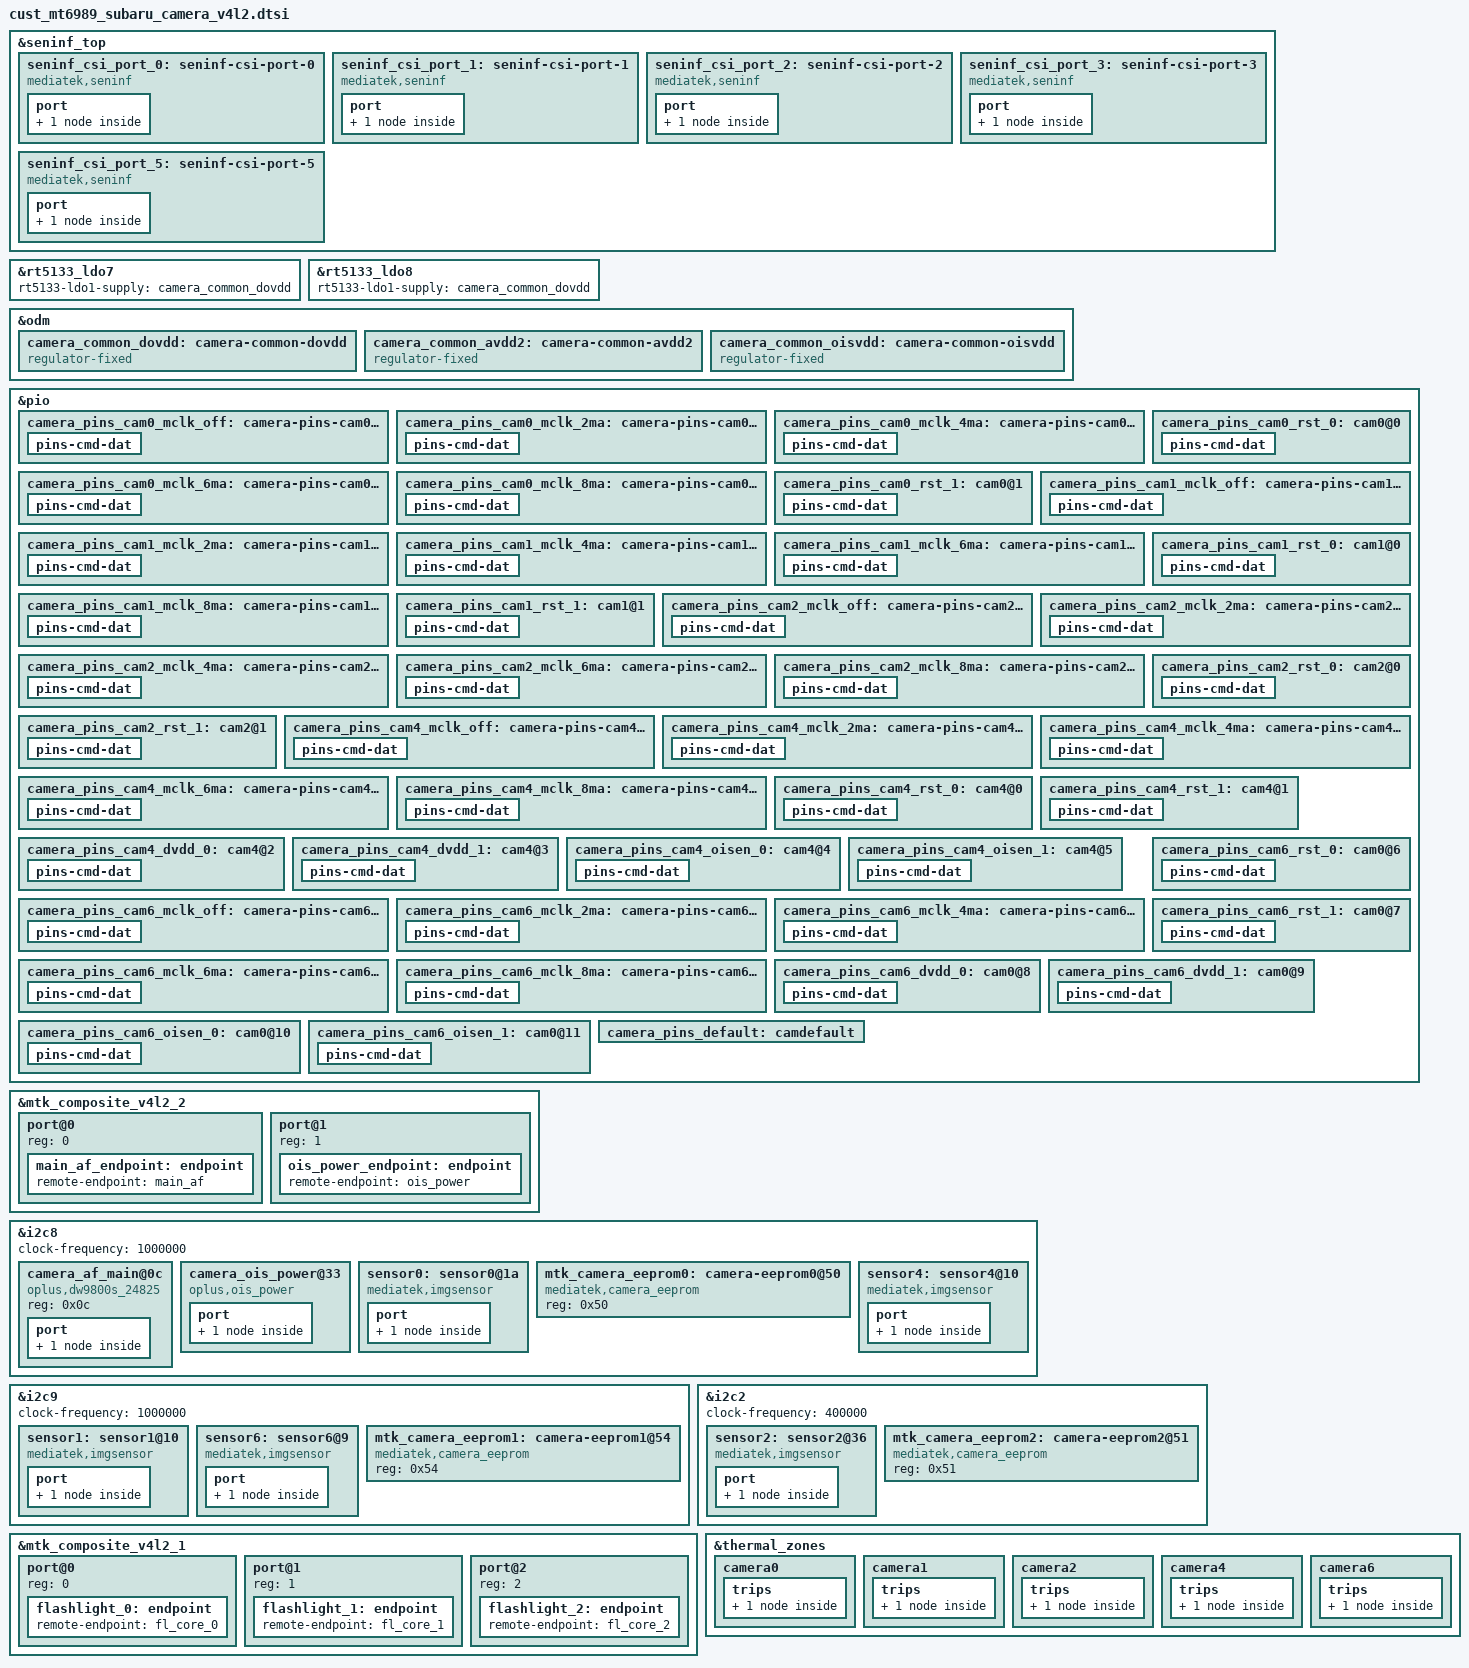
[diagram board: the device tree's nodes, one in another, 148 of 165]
// SPDX-License-Identifier: GPL-2.0
/* Copyright (c) 2020 MediaTek Inc. */
#include <dt-bindings/clock/mt6989-clk.h>
#include "mediatek/subaru_regulator_aw37004dnr.dtsi"
#include "../../../../../../vendor/oplus/kernel/camera/imgsensor/inc/oplus_kd_imgsensor.h"

&seninf_top {
		seninf_csi_port_0: seninf-csi-port-0 {
			compatible = "mediatek,seninf";
			csi-port = "0";

			nvmem-cells = <&csi_efuse0>;
			nvmem-cell-names = "rg_csi";

			port {
				seninf_csi_port_0_in: endpoint {
					remote-endpoint = <&sensor4_out>;
				};
			};
		};

		seninf_csi_port_1: seninf-csi-port-1 {
			compatible = "mediatek,seninf";
			csi-port = "1";

			nvmem-cells = <&csi_efuse1>;
			nvmem-cell-names = "rg_csi";

			port {
				seninf_csi_port_1_in: endpoint {
					remote-endpoint = <&sensor6_out>;
				};
			};
		};

		seninf_csi_port_2: seninf-csi-port-2 {
			compatible = "mediatek,seninf";
			csi-port = "2";

			nvmem-cells = <&csi_efuse2>;
			nvmem-cell-names = "rg_csi";
			port {
				seninf_csi_port_2_in: endpoint {
					remote-endpoint = <&sensor1_out>;
				};
			};
		};

		seninf_csi_port_3: seninf-csi-port-3 {
			compatible = "mediatek,seninf";
			csi-port = "3";

			nvmem-cells = <&csi_efuse3>;
			nvmem-cell-names = "rg_csi";
			port {
				seninf_csi_port_3_in: endpoint {
					remote-endpoint = <&sensor0_out>;
				};
			};
		};

		seninf_csi_port_5: seninf-csi-port-5 {
			compatible = "mediatek,seninf";
			csi-port = "5";

			nvmem-cells = <&csi_efuse5>;
			nvmem-cell-names = "rg_csi";
			port {
				seninf_csi_port_5_in: endpoint {
					remote-endpoint = <&sensor2_out>;
				};
			};
		};
};

&rt5133_ldo7 {
	rt5133-ldo1-supply = <&camera_common_dovdd>;
};

&rt5133_ldo8 {
	rt5133-ldo1-supply = <&camera_common_dovdd>;
};

/* CAMERA GPIO fixed to regulator */
&odm {
	camera_common_dovdd: camera-common-dovdd {
		compatible = "regulator-fixed";
		regulator-name = "camera-common-dovdd";
		regulator-min-microvolt = <1800000>;
		regulator-max-microvolt = <1800000>;
		enable-active-high;
		gpio = <&pio 92 0x0>;
	};
	camera_common_avdd2: camera-common-avdd2 {
		compatible = "regulator-fixed";
		regulator-name = "camera-common-avdd2";
		regulator-min-microvolt = <1800000>;
		regulator-max-microvolt = <1800000>;
		enable-active-high;
		gpio = <&pio 93 0x0>;
	};
	camera_common_oisvdd: camera-common-oisvdd {
		compatible = "regulator-fixed";
		regulator-name = "camera-common-oisvdd";
		regulator-min-microvolt = <1800000>;
		regulator-max-microvolt = <1800000>;
		enable-active-high;
		gpio = <&pio 94 0x0>;
	};
};

/* CAMERA GPIO standardization */
&pio {
	camera_pins_cam0_mclk_off: camera-pins-cam0-mclk-off {
		pins-cmd-dat {
			pinmux = <PINMUX_GPIO117__FUNC_GPIO117>;
			drive-strength = <1>;
		};
	};
	camera_pins_cam0_mclk_2ma: camera-pins-cam0-mclk-2ma {
		pins-cmd-dat {
			pinmux = <PINMUX_GPIO117__FUNC_CMMCLK3>;
			drive-strength = <0>;
		};
	};
	camera_pins_cam0_mclk_4ma: camera-pins-cam0-mclk-4ma {
		pins-cmd-dat {
			pinmux = <PINMUX_GPIO117__FUNC_CMMCLK3>;
			drive-strength = <1>;
		};
	};
	camera_pins_cam0_mclk_6ma: camera-pins-cam0-mclk-6ma {
		pins-cmd-dat {
			pinmux = <PINMUX_GPIO117__FUNC_CMMCLK3>;
			drive-strength = <2>;
		};
	};
	camera_pins_cam0_mclk_8ma: camera-pins-cam0-mclk-8ma {
		pins-cmd-dat {
			pinmux = <PINMUX_GPIO117__FUNC_CMMCLK3>;
			drive-strength = <3>;
		};
	};
	camera_pins_cam0_rst_0: cam0@0 {
		pins-cmd-dat {
			pinmux = <PINMUX_GPIO118__FUNC_GPIO118>;
			slew-rate = <1>;
			output-low;
		};
	};
	camera_pins_cam0_rst_1: cam0@1 {
		pins-cmd-dat {
			pinmux = <PINMUX_GPIO118__FUNC_GPIO118>;
			slew-rate = <1>;
			output-high;
		};
	};

	camera_pins_cam1_mclk_off: camera-pins-cam1-mclk-off {
		pins-cmd-dat {
			pinmux = <PINMUX_GPIO124__FUNC_GPIO124>;
			drive-strength = <1>;
		};
	};
	camera_pins_cam1_mclk_2ma: camera-pins-cam1-mclk-2ma {
		pins-cmd-dat {
			pinmux = <PINMUX_GPIO124__FUNC_CMMCLK0>;
			drive-strength = <0>;
		};
	};
	camera_pins_cam1_mclk_4ma: camera-pins-cam1-mclk-4ma {
		pins-cmd-dat {
			pinmux = <PINMUX_GPIO124__FUNC_CMMCLK0>;
			drive-strength = <1>;
		};
	};
	camera_pins_cam1_mclk_6ma: camera-pins-cam1-mclk-6ma {
		pins-cmd-dat {
			pinmux = <PINMUX_GPIO124__FUNC_CMMCLK0>;
			drive-strength = <2>;
		};
	};
	camera_pins_cam1_mclk_8ma: camera-pins-cam1-mclk-8ma {
		pins-cmd-dat {
			pinmux = <PINMUX_GPIO124__FUNC_CMMCLK0>;
			drive-strength = <3>;
		};
	};
	camera_pins_cam1_rst_0: cam1@0 {
		pins-cmd-dat {
			pinmux = <PINMUX_GPIO16__FUNC_GPIO16>;
			slew-rate = <1>;
			output-low;
		};
	};
	camera_pins_cam1_rst_1: cam1@1 {
		pins-cmd-dat {
			pinmux = <PINMUX_GPIO16__FUNC_GPIO16>;
			slew-rate = <1>;
			output-high;
		};
	};

	camera_pins_cam2_mclk_off: camera-pins-cam2-mclk-off {
		pins-cmd-dat {
			pinmux = <PINMUX_GPIO116__FUNC_GPIO116>;
			drive-strength = <1>;
		};
	};
	camera_pins_cam2_mclk_2ma: camera-pins-cam2-mclk-2ma {
		pins-cmd-dat {
			pinmux = <PINMUX_GPIO116__FUNC_CMMCLK2>;
			drive-strength = <0>;
		};
	};
	camera_pins_cam2_mclk_4ma: camera-pins-cam2-mclk-4ma {
		pins-cmd-dat {
			pinmux = <PINMUX_GPIO116__FUNC_CMMCLK2>;
			drive-strength = <1>;
		};
	};
	camera_pins_cam2_mclk_6ma: camera-pins-cam2-mclk-6ma {
		pins-cmd-dat {
			pinmux = <PINMUX_GPIO116__FUNC_CMMCLK2>;
			drive-strength = <2>;
		};
	};
	camera_pins_cam2_mclk_8ma: camera-pins-cam2-mclk-8ma {
		pins-cmd-dat {
			pinmux = <PINMUX_GPIO116__FUNC_CMMCLK2>;
			drive-strength = <3>;
		};
	};
	camera_pins_cam2_rst_0: cam2@0 {
		pins-cmd-dat {
			pinmux = <PINMUX_GPIO119__FUNC_GPIO119>;
			slew-rate = <1>;
			output-low;
		};
	};
	camera_pins_cam2_rst_1: cam2@1 {
		pins-cmd-dat {
			pinmux = <PINMUX_GPIO119__FUNC_GPIO119>;
			slew-rate = <1>;
			output-high;
		};
	};
	camera_pins_cam4_mclk_off: camera-pins-cam4-mclk-off {
		pins-cmd-dat {
			pinmux = <PINMUX_GPIO125__FUNC_GPIO125>;
			drive-strength = <1>;
		};
	};
	camera_pins_cam4_mclk_2ma: camera-pins-cam4-mclk-2ma {
		pins-cmd-dat {
			pinmux = <PINMUX_GPIO125__FUNC_CMMCLK1>;
			drive-strength = <0>;
		};
	};
	camera_pins_cam4_mclk_4ma: camera-pins-cam4-mclk-4ma {
		pins-cmd-dat {
			pinmux = <PINMUX_GPIO125__FUNC_CMMCLK1>;
			drive-strength = <1>;
		};
	};
	camera_pins_cam4_mclk_6ma: camera-pins-cam4-mclk-6ma {
		pins-cmd-dat {
			pinmux = <PINMUX_GPIO125__FUNC_CMMCLK1>;
			drive-strength = <2>;
		};
	};
	camera_pins_cam4_mclk_8ma: camera-pins-cam4-mclk-8ma {
		pins-cmd-dat {
			pinmux = <PINMUX_GPIO125__FUNC_CMMCLK1>;
			drive-strength = <3>;
		};
	};
	camera_pins_cam4_rst_0: cam4@0 {
		pins-cmd-dat {
			pinmux = <PINMUX_GPIO127__FUNC_GPIO127>;
			slew-rate = <1>;
			output-low;
		};
	};
	camera_pins_cam4_rst_1: cam4@1 {
		pins-cmd-dat {
			pinmux = <PINMUX_GPIO127__FUNC_GPIO127>;
			slew-rate = <1>;
			output-high;
		};
	};
	camera_pins_cam4_dvdd_0: cam4@2 {
		pins-cmd-dat {
			pinmux = <PINMUX_GPIO108__FUNC_GPIO108>;
			slew-rate = <1>;
			output-low;
		};
	};
	camera_pins_cam4_dvdd_1: cam4@3 {
		pins-cmd-dat {
			pinmux = <PINMUX_GPIO108__FUNC_GPIO108>;
			slew-rate = <1>;
			output-high;
		};
	};
	camera_pins_cam4_oisen_0: cam4@4 {
		pins-cmd-dat {
			pinmux = <PINMUX_GPIO189__FUNC_GPIO189>;
			slew-rate = <1>;
			output-low;
		};
	};
	camera_pins_cam4_oisen_1: cam4@5 {
		pins-cmd-dat {
			pinmux = <PINMUX_GPIO189__FUNC_GPIO189>;
			slew-rate = <1>;
			output-high;
		};
	};
	camera_pins_cam6_mclk_off: camera-pins-cam6-mclk-off {
		pins-cmd-dat {
			pinmux = <PINMUX_GPIO107__FUNC_GPIO107>;
			drive-strength = <1>;
		};
	};
	camera_pins_cam6_mclk_2ma: camera-pins-cam6-mclk-2ma {
		pins-cmd-dat {
			pinmux = <PINMUX_GPIO107__FUNC_CMMCLK5>;
			drive-strength = <0>;
		};
	};
	camera_pins_cam6_mclk_4ma: camera-pins-cam6-mclk-4ma {
		pins-cmd-dat {
			pinmux = <PINMUX_GPIO107__FUNC_CMMCLK5>;
			drive-strength = <1>;
		};
	};
	camera_pins_cam6_mclk_6ma: camera-pins-cam6-mclk-6ma {
		pins-cmd-dat {
			pinmux = <PINMUX_GPIO107__FUNC_CMMCLK5>;
			drive-strength = <2>;
		};
	};
	camera_pins_cam6_mclk_8ma: camera-pins-cam6-mclk-8ma {
		pins-cmd-dat {
			pinmux = <PINMUX_GPIO107__FUNC_CMMCLK5>;
			drive-strength = <3>;
		};
	};
	camera_pins_cam6_rst_0: cam0@6 {
		pins-cmd-dat {
			pinmux = <PINMUX_GPIO110__FUNC_GPIO110>;
			slew-rate = <1>;
			output-low;
		};
	};
	camera_pins_cam6_rst_1: cam0@7 {
		pins-cmd-dat {
			pinmux = <PINMUX_GPIO110__FUNC_GPIO110>;
			slew-rate = <1>;
			output-high;
		};
	};
	camera_pins_cam6_dvdd_0: cam0@8 {
		pins-cmd-dat {
			pinmux = <PINMUX_GPIO126__FUNC_GPIO126>;
			slew-rate = <1>;
			output-low;
		};
	};
	camera_pins_cam6_dvdd_1: cam0@9 {
		pins-cmd-dat {
			pinmux = <PINMUX_GPIO126__FUNC_GPIO126>;
			slew-rate = <1>;
			output-high;
		};
	};
	camera_pins_cam6_oisen_0: cam0@10 {
		pins-cmd-dat {
			pinmux = <PINMUX_GPIO223__FUNC_GPIO223>;
			slew-rate = <1>;
			output-low;
		};
	};
	camera_pins_cam6_oisen_1: cam0@11 {
		pins-cmd-dat {
			pinmux = <PINMUX_GPIO223__FUNC_GPIO223>;
			slew-rate = <1>;
			output-high;
		};
	};
	camera_pins_default: camdefault {
	};
};
/* CAMERA GPIO end */

&mtk_composite_v4l2_2 {
	#address-cells = <1>;
	#size-cells = <0>;

	port@0 {
		reg = <0>;
		main_af_endpoint: endpoint {
			remote-endpoint = <&main_af>;
		};
	};
	port@1 {
		reg = <1>;
		ois_power_endpoint: endpoint {
			remote-endpoint = <&ois_power>;
		};
	};
};

&i2c8 {
	status = "okay";
	clock-frequency = <1000000>;

	camera_af_main@0c {
		compatible = "oplus,dw9800s_24825";
		reg = <0x0c>;
		//vin-supply = <&mt6373_vcn33_1>;
		port {
			main_af: endpoint {
				remote-endpoint = <&main_af_endpoint>;
			};
		};
	};
	camera_ois_power@33 {
		compatible = "oplus,ois_power";
		reg = <0x33>;
		ois1-supply = <&mt6373_vcn33_2>;
		port {
			ois_power: endpoint {
				remote-endpoint = <&ois_power_endpoint>;
			};
		};
	};
	sensor0: sensor0@1a {
		compatible = "mediatek,imgsensor";
		sensor-names = SENSOR_DRVNAME_SUBARUMAIN_MIPI_RAW;
		sensor-ids = <SUBARUMAIN_SENSOR_ID>;
		sensor-hal-names = SENSOR_DRVNAME_SUBARUMAIN_MIPI_RAW;
		reg = <0x1a>;

		#thermal-sensor-cells = <0>;

		pinctrl-names = "mclk_off",
				"mclk_2mA",
				"mclk_4mA",
				"mclk_6mA",
				"mclk_8mA",
				"rst_low",
				"rst_high";
		pinctrl-0 = <&camera_pins_cam0_mclk_off>;
		pinctrl-1 = <&camera_pins_cam0_mclk_2ma>;
		pinctrl-2 = <&camera_pins_cam0_mclk_4ma>;
		pinctrl-3 = <&camera_pins_cam0_mclk_6ma>;
		pinctrl-4 = <&camera_pins_cam0_mclk_8ma>;
		pinctrl-5 = <&camera_pins_cam0_rst_0>;
		pinctrl-6 = <&camera_pins_cam0_rst_1>;

		avdd-supply = <&aw37004dnr_avdd1>;
		dvdd-supply = <&aw37004dnr_dvdd1>;
		afvdd-supply = <&mt6373_vcn33_1>;
		dovdd-supply = <&mt6373_vant18>;

		clocks = <&topckgen_clk CLK_TOP_UNIVPLL2_192M_D32>,
			<&topckgen_clk CLK_TOP_UNIVPLL2_192M_D16>,
			<&topckgen_clk CLK_TOP_F26M_CK_D2>,
			<&topckgen_clk CLK_TOP_UNIVPLL2_192M_D10>,
			<&topckgen_clk CLK_TOP_UNIVPLL2_192M_D8>,
			<&topckgen_clk CLK_TOP_UNIVPLL2_D6_D16>,
			<&topckgen_clk CLK_TOP_UNIVPLL2_D6_D8>,
			<&topckgen_clk CLK_TOP_CAMTG3_SEL>;  //mclk3
		clock-names = "6", "12", "13", "19.2", "24", "26", "52", "mclk";

		status = "okay";
		port {
			sensor0_out: endpoint {
				remote-endpoint = <&seninf_csi_port_3_in>;
			};
		};
	};

	mtk_camera_eeprom0:camera-eeprom0@50 {
		compatible = "mediatek,camera_eeprom";
		reg = <0x50>;
		status = "okay";
	};

	sensor4: sensor4@10 {
		compatible = "mediatek,imgsensor";
		sensor-names = "imx758_mipi_raw";
		reg = <0x10>;

		#thermal-sensor-cells = <0>;

		pinctrl-names = "mclk_off",
				"mclk_2mA",
				"mclk_4mA",
				"mclk_6mA",
				"mclk_8mA",
				"rst_low",
				"rst_high",
				"dvdd_off",
				"dvdd_on",
				"oisen_off",
				"oisen_on";
		pinctrl-0 = <&camera_pins_cam4_mclk_off>;
		pinctrl-1 = <&camera_pins_cam4_mclk_2ma>;
		pinctrl-2 = <&camera_pins_cam4_mclk_4ma>;
		pinctrl-3 = <&camera_pins_cam4_mclk_6ma>;
		pinctrl-4 = <&camera_pins_cam4_mclk_8ma>;
		pinctrl-5 = <&camera_pins_cam4_rst_0>;
		pinctrl-6 = <&camera_pins_cam4_rst_1>;
		pinctrl-7 = <&camera_pins_cam4_dvdd_0>;
		pinctrl-8 = <&camera_pins_cam4_dvdd_1>;
		pinctrl-9 = <&camera_pins_cam4_oisen_0>;
		pinctrl-10 = <&camera_pins_cam4_oisen_1>;

		avdd-supply = <&rt5133_ldo3>;
		afvdd-supply = <&rt5133_ldo2>;
		oisvdd-supply = <&rt5133_ldo1>;

		clocks = <&topckgen_clk CLK_TOP_UNIVPLL2_192M_D32>,
			<&topckgen_clk CLK_TOP_UNIVPLL2_192M_D16>,
			<&topckgen_clk CLK_TOP_F26M_CK_D2>,
			<&topckgen_clk CLK_TOP_UNIVPLL2_192M_D10>,
			<&topckgen_clk CLK_TOP_UNIVPLL2_192M_D8>,
			<&topckgen_clk CLK_TOP_UNIVPLL2_D6_D16>,
			<&topckgen_clk CLK_TOP_UNIVPLL2_D6_D8>,
			<&topckgen_clk CLK_TOP_CAMTG1_SEL>;
		clock-names = "6", "12", "13", "19.2", "24", "26", "52", "mclk";

		status = "okay";
		port {
			sensor4_out: endpoint {
				remote-endpoint = <&seninf_csi_port_0_in>;
			};
		};
	};
};

&i2c9 {
	status = "okay";
	clock-frequency = <1000000>;

	sensor1: sensor1@10 {
		compatible = "mediatek,imgsensor";
		sensor-names = SENSOR_DRVNAME_SUBARUFRONT_MIPI_RAW;
		sensor-ids = <SUBARUFRONT_SENSOR_ID>;
		sensor-hal-names = SENSOR_DRVNAME_SUBARUFRONT_MIPI_RAW;
		reg = <0x10>;
		#reindex-to = <0>;
		#cust-aov-csi-clk = <312>;
		#thermal-sensor-cells = <0>;

		pinctrl-names = "mclk1_off",
				"mclk1_2mA",
				"mclk1_4mA",
				"mclk1_6mA",
				"mclk1_8mA",
				"rst_low",
				"rst_high";

		pinctrl-0 = <&camera_pins_cam1_mclk_off>;
		pinctrl-1 = <&camera_pins_cam1_mclk_2ma>;
		pinctrl-2 = <&camera_pins_cam1_mclk_4ma>;
		pinctrl-3 = <&camera_pins_cam1_mclk_6ma>;
		pinctrl-4 = <&camera_pins_cam1_mclk_8ma>;
		pinctrl-5 = <&camera_pins_cam1_rst_0>;
		pinctrl-6 = <&camera_pins_cam1_rst_1>;

		avdd-supply = <&aw37004dnr_avdd2>;
		dvdd-supply = <&aw37004dnr_dvdd2>;
		dovdd-supply = <&mt6373_vant18>;

		clocks =<&topckgen_clk CLK_TOP_UNIVPLL_192M_D32>,
			<&topckgen_clk CLK_TOP_UNIVPLL_192M_D16>,
			<&topckgen_clk CLK_TOP_F26M_CK_D2>,
			<&topckgen_clk CLK_TOP_UNIVPLL_192M_D10>,
			<&topckgen_clk CLK_TOP_UNIVPLL_192M_D8>,
			<&topckgen_clk CLK_TOP_UNIVPLL_D6_D16>,
			<&topckgen_clk CLK_TOP_OSC_D20>,
			<&topckgen_clk CLK_TOP_UNIVPLL_D6_D8>,
			<&vlp_cksys_clk CLK_VLP_CK_CAMTG0_SEL>;
		clock-names ="clk1_6", "clk1_12", "clk1_13", "clk1_19.2",
			      "clk1_24", "clk1_26", "clk1_26_ulposc", "clk1_52", "clk1_mclk1";

		status = "okay";
		port {
			sensor1_out: endpoint {
				remote-endpoint = <&seninf_csi_port_2_in>;
			};
		};
	};

	sensor6: sensor6@9 {
		compatible = "mediatek,imgsensor";
		sensor-names = "ov64b_mipi_raw";
		reg = <0x9>;

		#thermal-sensor-cells = <0>;

		pinctrl-names = "mclk_off",
				"mclk_2mA",
				"mclk_4mA",
				"mclk_6mA",
				"mclk_8mA",
				"rst_low",
				"rst_high",
				"dvdd_off",
				"dvdd_on",
				"oisen_off",
				"oisen_on";
		pinctrl-0 = <&camera_pins_cam6_mclk_off>;
		pinctrl-1 = <&camera_pins_cam6_mclk_2ma>;
		pinctrl-2 = <&camera_pins_cam6_mclk_4ma>;
		pinctrl-3 = <&camera_pins_cam6_mclk_6ma>;
		pinctrl-4 = <&camera_pins_cam6_mclk_8ma>;
		pinctrl-5 = <&camera_pins_cam6_rst_0>;
		pinctrl-6 = <&camera_pins_cam6_rst_1>;
		pinctrl-7 = <&camera_pins_cam6_dvdd_0>;
		pinctrl-8 = <&camera_pins_cam6_dvdd_1>;
		pinctrl-9 = <&camera_pins_cam6_oisen_0>;
		pinctrl-10 = <&camera_pins_cam6_oisen_1>;

		avdd-supply = <&rt5133_ldo4>;
		afvdd1-supply = <&rt5133_gpio1>;

		clocks = <&topckgen_clk CLK_TOP_UNIVPLL2_192M_D32>,
			<&topckgen_clk CLK_TOP_UNIVPLL2_192M_D16>,
			<&topckgen_clk CLK_TOP_F26M_CK_D2>,
			<&topckgen_clk CLK_TOP_UNIVPLL2_192M_D10>,
			<&topckgen_clk CLK_TOP_UNIVPLL2_192M_D8>,
			<&topckgen_clk CLK_TOP_UNIVPLL2_D6_D16>,
			<&topckgen_clk CLK_TOP_UNIVPLL2_D6_D8>,
			<&topckgen_clk CLK_TOP_CAMTG5_SEL>;
		clock-names = "6", "12", "13", "19.2", "24", "26", "52", "mclk";

		status = "okay";
		port {
			sensor6_out: endpoint {
				remote-endpoint = <&seninf_csi_port_1_in>;
			};
		};
	};
	mtk_camera_eeprom1:camera-eeprom1@54 {
		compatible = "mediatek,camera_eeprom";
		reg = <0x54>;
		status = "okay";
	};
};

&i2c2 {
	status = "okay";
	clock-frequency = <400000>;

	sensor2: sensor2@36 {
		compatible = "mediatek,imgsensor";
		sensor-names = SENSOR_DRVNAME_SUBARUMONO_MIPI_RAW;
		sensor-ids = <SUBARUMONO_SENSOR_ID>;
		sensor-hal-names = SENSOR_DRVNAME_SUBARUMONO_MIPI_RAW;
		reg = <0x36>;
		#reindex-to = <0>;
		#cust-aov-csi-clk = <312>;
		#thermal-sensor-cells = <0>;

		pinctrl-names = "mclk_off",
				"mclk_2mA",
				"mclk_4mA",
				"mclk_6mA",
				"mclk_8mA",
				"rst_low",
				"rst_high";

		pinctrl-0 = <&camera_pins_cam2_mclk_off>;
		pinctrl-1 = <&camera_pins_cam2_mclk_2ma>;
		pinctrl-2 = <&camera_pins_cam2_mclk_4ma>;
		pinctrl-3 = <&camera_pins_cam2_mclk_6ma>;
		pinctrl-4 = <&camera_pins_cam2_mclk_8ma>;
		pinctrl-5 = <&camera_pins_cam2_rst_0>;
		pinctrl-6 = <&camera_pins_cam2_rst_1>;

		avdd-supply = <&aw37004dnr_avdd2>;
		//dvdd-supply = <&mt6373_vant18>;
		dovdd-supply = <&mt6373_vant18>;

		clocks = <&topckgen_clk CLK_TOP_UNIVPLL2_192M_D32>,
			<&topckgen_clk CLK_TOP_UNIVPLL2_192M_D16>,
			<&topckgen_clk CLK_TOP_F26M_CK_D2>,
			<&topckgen_clk CLK_TOP_UNIVPLL2_192M_D10>,
			<&topckgen_clk CLK_TOP_UNIVPLL2_192M_D8>,
			<&topckgen_clk CLK_TOP_UNIVPLL2_D6_D16>,
			<&topckgen_clk CLK_TOP_UNIVPLL2_D6_D8>,
			<&topckgen_clk CLK_TOP_CAMTG2_SEL>;  //mclk2
		clock-names = "6", "12", "13", "19.2", "24", "26", "52", "mclk";

		status = "okay";
		port {
			sensor2_out: endpoint {
				remote-endpoint = <&seninf_csi_port_5_in>;
			};
		};
	};

	mtk_camera_eeprom2:camera-eeprom2@51 {
		compatible = "mediatek,camera_eeprom";
		reg = <0x51>;
		status = "okay";
	};
};

&mtk_composite_v4l2_1 {
	#address-cells = <1>;
	#size-cells = <0>;
	port@0 {
		reg = <0>;
		flashlight_0: endpoint {
			remote-endpoint = <&fl_core_0>;
		};
	};
	port@1 {
		reg = <1>;
		flashlight_1: endpoint {
			remote-endpoint = <&fl_core_1>;
		};
	};
	port@2 {
		reg = <2>;
		flashlight_2: endpoint {
			remote-endpoint = <&fl_core_2>;
		};
	};
};


&thermal_zones {
	camera0: camera0 {
		polling-delay = <0>; /* milliseconds */
		polling-delay-passive = <0>; /* milliseconds */
		thermal-sensors = <&sensor0>;
		trips {
			camera0_crit: camera0-crit {
				temperature = <120000>;
				hysteresis = <2000>;
				type = "passive";
			};
		};
	};
	camera1: camera1 {
		polling-delay = <0>; /* milliseconds */
		polling-delay-passive = <0>; /* milliseconds */
		thermal-sensors = <&sensor1>;
		trips {
			camera1_crit: camera1-crit {
				temperature = <120000>;
				hysteresis = <2000>;
				type = "passive";
			};
		};
	};
	camera2: camera2 {
		polling-delay = <0>; /* milliseconds */
		polling-delay-passive = <0>; /* milliseconds */
		thermal-sensors = <&sensor2>;
		trips {
			camera2_crit: camera2-crit {
				temperature = <120000>;
				hysteresis = <2000>;
				type = "passive";
			};
		};
	};
	camera4: camera4 {
		polling-delay = <0>; /* milliseconds */
		polling-delay-passive = <0>; /* milliseconds */
		thermal-sensors = <&sensor4>;
		trips {
			camera4_crit: camera4-crit {
				temperature = <120000>;
				hysteresis = <2000>;
				type = "passive";
			};
		};
	};
	camera6: camera6 {
		polling-delay = <0>; /* milliseconds */
		polling-delay-passive = <0>; /* milliseconds */
		thermal-sensors = <&sensor6>;
		trips {
			camera6_crit: camera6-crit {
				temperature = <120000>;
				hysteresis = <2000>;
				type = "passive";
			};
		};
	};
};
